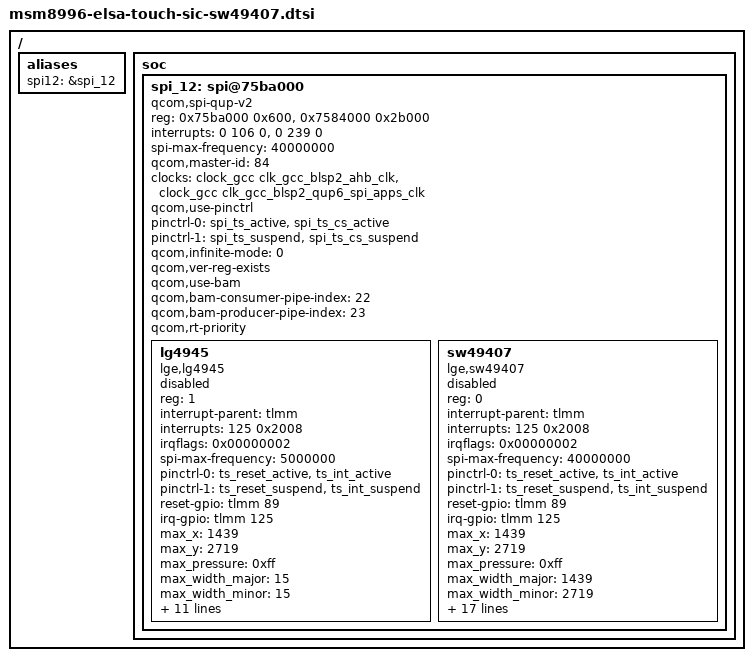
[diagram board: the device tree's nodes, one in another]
/* Copyright (c) 2014, The Linux Foundation. All rights reserved.
 *
 * This program is free software; you can redistribute it and/or modify
 * it under the terms of the GNU General Public License version 2 and
 * only version 2 as published by the Free Software Foundation.
 *
 * This program is distributed in the hope that it will be useful,
 * but WITHOUT ANY WARRANTY; without even the implied warranty of
 * MERCHANTABILITY or FITNESS FOR A PARTICULAR PURPOSE.  See the
 * GNU General Public License for more details.
 */

/ {
	aliases {
		spi12 = &spi_12;
	};

	soc {
		spi_12: spi@75ba000{    /* BLSP-2 QUP6 */
			status = "ok";
			compatible = "qcom,spi-qup-v2";

			#address-cells = <1>;
			#size-cells = <0>;

			reg-names = "spi_physical", "spi_bam_physical";
			reg = <0x75ba000 0x600>, <0x7584000 0x2b000>;

			interrupt-names = "spi_irq", "spi_bam_irq";
			interrupts = <0 106 0>, <0 239 0>;

			spi-max-frequency = <40000000>;
			qcom,master-id = <84>;

			clock-names = "iface_clk", "core_clk";
			clocks = <&clock_gcc clk_gcc_blsp2_ahb_clk>,
					 <&clock_gcc clk_gcc_blsp2_qup6_spi_apps_clk>;

			/* Assign runtime functions to pins */
			qcom,use-pinctrl;
			pinctrl-names = "spi_default","spi_sleep";
			pinctrl-0 = <&spi_ts_active &spi_ts_cs_active>;
			pinctrl-1 = <&spi_ts_suspend &spi_ts_cs_suspend>;

			qcom,infinite-mode = <0>;
			qcom,ver-reg-exists;

			qcom,use-bam;
			qcom,bam-consumer-pipe-index = <22>;
			qcom,bam-producer-pipe-index = <23>;
			qcom,rt-priority;

			lg4945 {
				compatible = "lge,lg4945";
				reg = <1>;
				status = "disabled";
				interrupt-parent = <&tlmm>;
				interrupts = <125 0x2008>;

				irqflags = <0x00000002>;
				spi-max-frequency = <5000000>;

				pinctrl-names = "touch_pin_active", "touch_pin_sleep";
				pinctrl-0 = <&ts_reset_active &ts_int_active>;
				pinctrl-1 = <&ts_reset_suspend &ts_int_suspend>;

				reset-gpio = <&tlmm 89 0x00>;
				irq-gpio = <&tlmm 125 0x2008>;

				/*Caps*/
				max_x = <1439>;
				max_y = <2719>;
				max_pressure = <0xff>;
				max_width_major = <15>;
				max_width_minor = <15>;
				max_orientation = <1>;
				max_id = <10>;

				/*role*/
				hw_reset_delay = <90>;
				sw_reset_delay = <10>;
				use_lpwg = <1>;
				use_lpwg_test = <1>;

				/* firmware */
				fw_image = "touch/elsa/L0L57P1_2_00.img",
						"touch/elsa/L0L57P1_1_35.img";
				panel_spec = "touch/elsa/elsa_limit.txt";
				panel_spec_mfts_folder = "touch/elsa/elsa_limit_mfts.txt";
			};

			sw49407 {
				compatible = "lge,sw49407";
				reg = <0>;
				status = "disabled";
				interrupt-parent = <&tlmm>;
				interrupts = <125 0x2008>;
				irqflags = <0x00000002>;
				spi-max-frequency = <40000000>;

				pinctrl-names = "touch_pin_active", "touch_pin_sleep";
				pinctrl-0 = <&ts_reset_active &ts_int_active>;
				pinctrl-1 = <&ts_reset_suspend &ts_int_suspend>;

				reset-gpio = <&tlmm 89 0x00>;
				irq-gpio = <&tlmm 125 0x2008>;

				/* Caps */
				max_x = <1439>;
				max_y = <2719>;
				max_pressure = <0xff>;
				max_width_major = <1439>;
				max_width_minor = <2719>;
				max_orientation = <90>;
				max_id = <10>;
				hw_reset_delay = <90>;
				sw_reset_delay = <10>;

				/* Role */
				use_lpwg = <1>;
				use_lpwg_test = <1>;
				use_upgrade = <1>;
				hide_coordinate = <1>;

				/* Firmware */
				fw_image = "touch/elsa/L1L57P1_1_14.img",
						"touch/elsa/L1L57P1_1_14.img";

				panel_spec = "touch/elsa/elsa_limit.txt";
				panel_spec_mfts_folder = "touch/elsa/elsa_limit_mfts.txt";

				/* ASC */
				use_asc = <0>;
				low_delta_thres = <350>;
				high_delta_thres = <600>;
				max_delta_cnt = <2>;
			};
		};
	};
};
